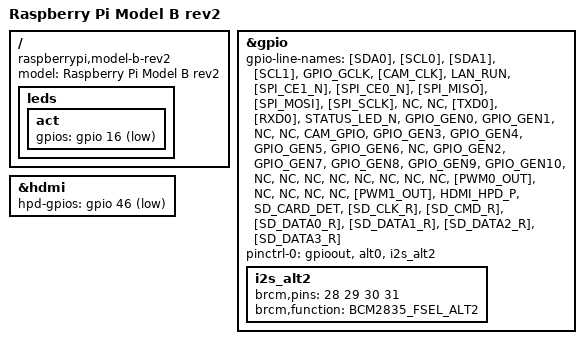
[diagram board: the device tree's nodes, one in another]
/dts-v1/;
#include "bcm2835.dtsi"
#include "bcm2835-rpi.dtsi"
#include "bcm283x-rpi-smsc9512.dtsi"
#include "bcm283x-rpi-usb-host.dtsi"

/ {
	compatible = "raspberrypi,model-b-rev2", "brcm,bcm2835";
	model = "Raspberry Pi Model B rev2";

	leds {
		act {
			gpios = <&gpio 16 1>;
		};
	};
};

&gpio {
	/*
	 * Taken from Raspberry-Pi-Rev-2.0-Model-AB-Schematics.pdf
	 * RPI00022 sheet 02
	 *
	 * Legend:
	 * "NC" = not connected (no rail from the SoC)
	 * "[FOO]" = pin is muxed for peripheral FOO (not GPIO)
	 * "" = No idea
	 * "FOO" = GPIO line named "FOO" on the schematic
	 * "FOO_N" = GPIO line named "FOO" on schematic, active low
	 */
	gpio-line-names = "[SDA0]", "[SCL0]", "[SDA1]", "[SCL1]",
			  "GPIO_GCLK", "[CAM_CLK]", "LAN_RUN",
			  "[SPI_CE1_N]", "[SPI_CE0_N]", "[SPI_MISO]",
			  "[SPI_MOSI]", "[SPI_SCLK]",
			  "NC", "NC", /* GPIO 12 & 13 unused */
			  "[TXD0]", "[RXD0]", /* Serial port */
			  "STATUS_LED_N",
			  "GPIO_GEN0", "GPIO_GEN1",
			  "NC", "NC", /* GPIO 19 & 20 unused */
			  "CAM_GPIO", "GPIO_GEN3", "GPIO_GEN4",
			  "GPIO_GEN5", "GPIO_GEN6",
			  "NC", /* GPIO 26 unused */
			  "GPIO_GEN2", "GPIO_GEN7", "GPIO_GEN8",
			  "GPIO_GEN9", "GPIO_GEN10",
			  /* GPIOs 32 thru 39 unused */
			  "NC", "NC", "NC", "NC", "NC", "NC", "NC", "NC",
			  "[PWM0_OUT]",
			  /* GPIOs 41 thru 44 unused */
			  "NC", "NC", "NC", "NC",
			  "[PWM1_OUT]",
			  /* FIXME: GPIO or device? */
			  "HDMI_HPD_P", "SD_CARD_DET",
			  /* Used by SD Card */
			  "[SD_CLK_R]", "[SD_CMD_R]", "[SD_DATA0_R]",
			  "[SD_DATA1_R]", "[SD_DATA2_R]", "[SD_DATA3_R]";

	pinctrl-0 = <&gpioout &alt0 &i2s_alt2>;

	/* I2S interface */
	i2s_alt2: i2s_alt2 {
		brcm,pins = <28 29 30 31>;
		brcm,function = <BCM2835_FSEL_ALT2>;
	};
};

&hdmi {
	hpd-gpios = <&gpio 46 GPIO_ACTIVE_LOW>;
};
